AUTOSAR XML (schema 00047)
package /ApplicationSwComponentTypesAR
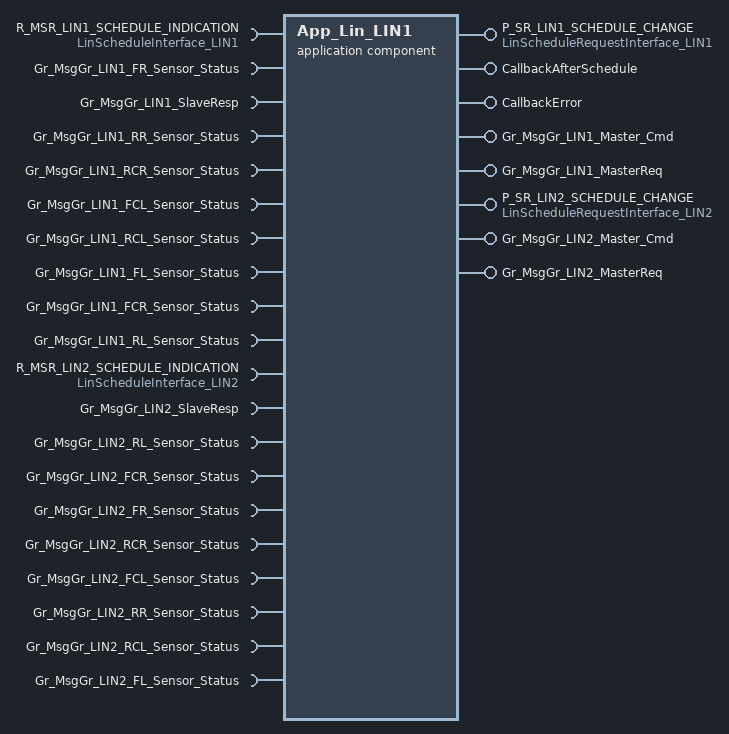
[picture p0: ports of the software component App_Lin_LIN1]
  application sw component type App_Lin_LIN1
    require port R_MSR_LIN1_SCHEDULE_INDICATION: mode-switch-receiver-com-spec{enhanced-mode-api=true, mode-group=LinSchedule_LIN1, supports-asynchronous-mode-switch=true}, required-interface=LinScheduleInterface_LIN1
    5 x provide port:
      P_SR_LIN1_SCHEDULE_CHANGE: nonqueued-sender-com-spec=data-element=LinSchedule_LIN1, provided-interface=LinScheduleRequestInterface_LIN1
      CallbackAfterSchedule: server-com-spec{operation=lin_after_schedule, queue-length=1}, provided-interface=CallbackAfterSchedule
      CallbackError: server-com-spec{operation=lin_cbk_err, queue-length=1}, provided-interface=CallbackError
      Gr_MsgGr_LIN1_Master_Cmd: nonqueued-sender-com-spec=data-element=MsgGr_LIN1_Master_Cmd, provided-interface=Gr_MsgGr_LIN1_Master_Cmd
      Gr_MsgGr_LIN1_MasterReq: nonqueued-sender-com-spec=data-element=MsgGr_LIN1_MasterReq, provided-interface=Gr_MsgGr_LIN1_MasterReq
    10 x require port:
      Gr_MsgGr_LIN1_FR_Sensor_Status: nonqueued-receiver-com-spec=data-element=MsgGr_LIN1_FR_Sensor_Status, required-interface=Gr_MsgGr_LIN1_FR_Sensor_Status
      Gr_MsgGr_LIN1_SlaveResp: nonqueued-receiver-com-spec=data-element=MsgGr_LIN1_SlaveResp, required-interface=Gr_MsgGr_LIN1_SlaveResp
      Gr_MsgGr_LIN1_RR_Sensor_Status: nonqueued-receiver-com-spec=data-element=MsgGr_LIN1_RR_Sensor_Status, required-interface=Gr_MsgGr_LIN1_RR_Sensor_Status
      Gr_MsgGr_LIN1_RCR_Sensor_Status: nonqueued-receiver-com-spec=data-element=MsgGr_LIN1_RCR_Sensor_Status, required-interface=Gr_MsgGr_LIN1_RCR_Sensor_Status
      Gr_MsgGr_LIN1_FCL_Sensor_Status: nonqueued-receiver-com-spec=data-element=MsgGr_LIN1_FCL_Sensor_Status, required-interface=Gr_MsgGr_LIN1_FCL_Sensor_Status
      Gr_MsgGr_LIN1_RCL_Sensor_Status: nonqueued-receiver-com-spec=data-element=MsgGr_LIN1_RCL_Sensor_Status, required-interface=Gr_MsgGr_LIN1_RCL_Sensor_Status
      Gr_MsgGr_LIN1_FL_Sensor_Status: nonqueued-receiver-com-spec=data-element=MsgGr_LIN1_FL_Sensor_Status, required-interface=Gr_MsgGr_LIN1_FL_Sensor_Status
      Gr_MsgGr_LIN1_FCR_Sensor_Status: nonqueued-receiver-com-spec=data-element=MsgGr_LIN1_FCR_Sensor_Status, required-interface=Gr_MsgGr_LIN1_FCR_Sensor_Status
      Gr_MsgGr_LIN1_RL_Sensor_Status: nonqueued-receiver-com-spec=data-element=MsgGr_LIN1_RL_Sensor_Status, required-interface=Gr_MsgGr_LIN1_RL_Sensor_Status
      R_MSR_LIN2_SCHEDULE_INDICATION: mode-switch-receiver-com-spec{enhanced-mode-api=true, mode-group=LinSchedule_LIN2, supports-asynchronous-mode-switch=true}, required-interface=LinScheduleInterface_LIN2
    provide port P_SR_LIN2_SCHEDULE_CHANGE: nonqueued-sender-com-spec=LinSchedule_LIN2, provided-interface=LinScheduleRequestInterface_LIN2
    provide port Gr_MsgGr_LIN2_Master_Cmd: nonqueued-sender-com-spec=MsgGr_LIN2_Master_Cmd, provided-interface=Gr_MsgGr_LIN2_Master_Cmd
    provide port Gr_MsgGr_LIN2_MasterReq: nonqueued-sender-com-spec=MsgGr_LIN2_MasterReq, provided-interface=Gr_MsgGr_LIN2_MasterReq
    9 x require port:
      Gr_MsgGr_LIN2_SlaveResp: nonqueued-receiver-com-spec=data-element=MsgGr_LIN2_SlaveResp, required-interface=Gr_MsgGr_LIN2_SlaveResp
      Gr_MsgGr_LIN2_RL_Sensor_Status: nonqueued-receiver-com-spec=data-element=MsgGr_LIN2_RL_Sensor_Status, required-interface=Gr_MsgGr_LIN2_RL_Sensor_Status
      Gr_MsgGr_LIN2_FCR_Sensor_Status: nonqueued-receiver-com-spec=data-element=MsgGr_LIN2_FCR_Sensor_Status, required-interface=Gr_MsgGr_LIN2_FCR_Sensor_Status
      Gr_MsgGr_LIN2_FR_Sensor_Status: nonqueued-receiver-com-spec=data-element=MsgGr_LIN2_FR_Sensor_Status, required-interface=Gr_MsgGr_LIN2_FR_Sensor_Status
      Gr_MsgGr_LIN2_RCR_Sensor_Status: nonqueued-receiver-com-spec=data-element=MsgGr_LIN2_RCR_Sensor_Status, required-interface=Gr_MsgGr_LIN2_RCR_Sensor_Status
      Gr_MsgGr_LIN2_FCL_Sensor_Status: nonqueued-receiver-com-spec=data-element=MsgGr_LIN2_FCL_Sensor_Status, required-interface=Gr_MsgGr_LIN2_FCL_Sensor_Status
      Gr_MsgGr_LIN2_RR_Sensor_Status: nonqueued-receiver-com-spec=data-element=MsgGr_LIN2_RR_Sensor_Status, required-interface=Gr_MsgGr_LIN2_RR_Sensor_Status
      Gr_MsgGr_LIN2_RCL_Sensor_Status: nonqueued-receiver-com-spec=data-element=MsgGr_LIN2_RCL_Sensor_Status, required-interface=Gr_MsgGr_LIN2_RCL_Sensor_Status
      Gr_MsgGr_LIN2_FL_Sensor_Status: nonqueued-receiver-com-spec=data-element=MsgGr_LIN2_FL_Sensor_Status, required-interface=Gr_MsgGr_LIN2_FL_Sensor_Status
    behavior SwcIB_App_LIN1: data-type-mapping=[MAP_LinSMState, MAP_LinSchedule_LIN1, MAP_LinSchedule_LIN2], handle-termination-and-restart=NO-SUPPORT
      operation invoked event OIE_RE_after_schedule_CBAfterSchedule_lin_after_schedule: start-on-event=RE_after_schedule, operation=CallbackAfterSchedule.lin_after_schedule
      operation invoked event OIE_RE_cbk_err_CBCbkErr_lin_cbk_err: start-on-event=RE_cbk_err, operation=CallbackError.lin_cbk_err
      46 x swc mode switch event, all with activation=ON-ENTRY:
        SMSE_Entry_Lin_LIN1_ScheduleSwitch_R_MSR_LIN_SCHEDULE_INDICATION_LinSchedule_LIN1_NULL: start-on-event=Lin_LIN1_ScheduleSwitch, mode=R_MSR_LIN1_SCHEDULE_INDICATION.LinSchedule_LIN1.NULL
        SMSE_Entry_Lin_LIN1_ScheduleSwitch_R_MSR_LIN_SCHEDULE_INDICATION_LinSchedule_LIN1_SCHEDULER_FPAS_TUNNING_WRITE: start-on-event=Lin_LIN1_ScheduleSwitch, mode=R_MSR_LIN1_SCHEDULE_INDICATION.LinSchedule_LIN1.SCHEDULER_FPAS_TUNNING_WRITE
        SMSE_Entry_Lin_LIN1_ScheduleSwitch_R_MSR_LIN_SCHEDULE_INDICATION_LinSchedule_LIN1_SCHEDULER_FPAS_VER_CHECK: start-on-event=Lin_LIN1_ScheduleSwitch, mode=R_MSR_LIN1_SCHEDULE_INDICATION.LinSchedule_LIN1.SCHEDULER_FPAS_VER_CHECK
        SMSE_Entry_Lin_LIN1_ScheduleSwitch_R_MSR_LIN_SCHEDULE_INDICATION_LinSchedule_LIN1_SCHEDULER_FRONT_PAS_NORMAL: start-on-event=Lin_LIN1_ScheduleSwitch, mode=R_MSR_LIN1_SCHEDULE_INDICATION.LinSchedule_LIN1.SCHEDULER_FRONT_PAS_NORMAL
        SMSE_Entry_Lin_LIN1_ScheduleSwitch_R_MSR_LIN_SCHEDULE_INDICATION_LinSchedule_LIN1_SCHEDULER_PAS_CRC_COMPARE: start-on-event=Lin_LIN1_ScheduleSwitch, mode=R_MSR_LIN1_SCHEDULE_INDICATION.LinSchedule_LIN1.SCHEDULER_PAS_CRC_COMPARE
        SMSE_Entry_Lin_LIN1_ScheduleSwitch_R_MSR_LIN_SCHEDULE_INDICATION_LinSchedule_LIN1_SCHEDULER_PAS_DIAG: start-on-event=Lin_LIN1_ScheduleSwitch, mode=R_MSR_LIN1_SCHEDULE_INDICATION.LinSchedule_LIN1.SCHEDULER_PAS_DIAG
        SMSE_Entry_Lin_LIN1_ScheduleSwitch_R_MSR_LIN_SCHEDULE_INDICATION_LinSchedule_LIN1_SCHEDULER_PAS_DIAG_FCL: start-on-event=Lin_LIN1_ScheduleSwitch, mode=R_MSR_LIN1_SCHEDULE_INDICATION.LinSchedule_LIN1.SCHEDULER_PAS_DIAG_FCL
        SMSE_Entry_Lin_LIN1_ScheduleSwitch_R_MSR_LIN_SCHEDULE_INDICATION_LinSchedule_LIN1_SCHEDULER_PAS_DIAG_FCR: start-on-event=Lin_LIN1_ScheduleSwitch, mode=R_MSR_LIN1_SCHEDULE_INDICATION.LinSchedule_LIN1.SCHEDULER_PAS_DIAG_FCR
        SMSE_Entry_Lin_LIN1_ScheduleSwitch_R_MSR_LIN_SCHEDULE_INDICATION_LinSchedule_LIN1_SCHEDULER_PAS_DIAG_FL: start-on-event=Lin_LIN1_ScheduleSwitch, mode=R_MSR_LIN1_SCHEDULE_INDICATION.LinSchedule_LIN1.SCHEDULER_PAS_DIAG_FL
        SMSE_Entry_Lin_LIN1_ScheduleSwitch_R_MSR_LIN_SCHEDULE_INDICATION_LinSchedule_LIN1_SCHEDULER_PAS_DIAG_FR: start-on-event=Lin_LIN1_ScheduleSwitch, mode=R_MSR_LIN1_SCHEDULE_INDICATION.LinSchedule_LIN1.SCHEDULER_PAS_DIAG_FR
        SMSE_Entry_Lin_LIN1_ScheduleSwitch_R_MSR_LIN_SCHEDULE_INDICATION_LinSchedule_LIN1_SCHEDULER_PAS_DIAG_IBU: start-on-event=Lin_LIN1_ScheduleSwitch, mode=R_MSR_LIN1_SCHEDULE_INDICATION.LinSchedule_LIN1.SCHEDULER_PAS_DIAG_IBU
        SMSE_Entry_Lin_LIN1_ScheduleSwitch_R_MSR_LIN_SCHEDULE_INDICATION_LinSchedule_LIN1_SCHEDULER_PAS_DIAG_RCL: start-on-event=Lin_LIN1_ScheduleSwitch, mode=R_MSR_LIN1_SCHEDULE_INDICATION.LinSchedule_LIN1.SCHEDULER_PAS_DIAG_RCL
        SMSE_Entry_Lin_LIN1_ScheduleSwitch_R_MSR_LIN_SCHEDULE_INDICATION_LinSchedule_LIN1_SCHEDULER_PAS_DIAG_RCR: start-on-event=Lin_LIN1_ScheduleSwitch, mode=R_MSR_LIN1_SCHEDULE_INDICATION.LinSchedule_LIN1.SCHEDULER_PAS_DIAG_RCR
        SMSE_Entry_Lin_LIN1_ScheduleSwitch_R_MSR_LIN_SCHEDULE_INDICATION_LinSchedule_LIN1_SCHEDULER_PAS_DIAG_RL: start-on-event=Lin_LIN1_ScheduleSwitch, mode=R_MSR_LIN1_SCHEDULE_INDICATION.LinSchedule_LIN1.SCHEDULER_PAS_DIAG_RL
        SMSE_Entry_Lin_LIN1_ScheduleSwitch_R_MSR_LIN_SCHEDULE_INDICATION_LinSchedule_LIN1_SCHEDULER_PAS_DIAG_RR: start-on-event=Lin_LIN1_ScheduleSwitch, mode=R_MSR_LIN1_SCHEDULE_INDICATION.LinSchedule_LIN1.SCHEDULER_PAS_DIAG_RR
        SMSE_Entry_Lin_LIN1_ScheduleSwitch_R_MSR_LIN_SCHEDULE_INDICATION_LinSchedule_LIN1_SCHEDULER_PAS_NORMAL: start-on-event=Lin_LIN1_ScheduleSwitch, mode=R_MSR_LIN1_SCHEDULE_INDICATION.LinSchedule_LIN1.SCHEDULER_PAS_NORMAL
        SMSE_Entry_Lin_LIN1_ScheduleSwitch_R_MSR_LIN_SCHEDULE_INDICATION_LinSchedule_LIN1_SCHEDULER_PAS_SENSOR_REQUEST: start-on-event=Lin_LIN1_ScheduleSwitch, mode=R_MSR_LIN1_SCHEDULE_INDICATION.LinSchedule_LIN1.SCHEDULER_PAS_SENSOR_REQUEST
        SMSE_Entry_Lin_LIN1_ScheduleSwitch_R_MSR_LIN_SCHEDULE_INDICATION_LinSchedule_LIN1_SCHEDULER_PAS_TEMP_COMP: start-on-event=Lin_LIN1_ScheduleSwitch, mode=R_MSR_LIN1_SCHEDULE_INDICATION.LinSchedule_LIN1.SCHEDULER_PAS_TEMP_COMP
        SMSE_Entry_Lin_LIN1_ScheduleSwitch_R_MSR_LIN_SCHEDULE_INDICATION_LinSchedule_LIN1_SCHEDULER_RPAS_CRC_COMPARE: start-on-event=Lin_LIN1_ScheduleSwitch, mode=R_MSR_LIN1_SCHEDULE_INDICATION.LinSchedule_LIN1.SCHEDULER_RPAS_CRC_COMPARE
        SMSE_Entry_Lin_LIN1_ScheduleSwitch_R_MSR_LIN_SCHEDULE_INDICATION_LinSchedule_LIN1_SCHEDULER_RPAS_NORMAL: start-on-event=Lin_LIN1_ScheduleSwitch, mode=R_MSR_LIN1_SCHEDULE_INDICATION.LinSchedule_LIN1.SCHEDULER_RPAS_NORMAL
        SMSE_Entry_Lin_LIN1_ScheduleSwitch_R_MSR_LIN_SCHEDULE_INDICATION_LinSchedule_LIN1_SCHEDULER_RPAS_TEMP_COMP: start-on-event=Lin_LIN1_ScheduleSwitch, mode=R_MSR_LIN1_SCHEDULE_INDICATION.LinSchedule_LIN1.SCHEDULER_RPAS_TEMP_COMP
        SMSE_Entry_Lin_LIN1_ScheduleSwitch_R_MSR_LIN_SCHEDULE_INDICATION_LinSchedule_LIN1_SCHEDULER_RPAS_TUNNING_WRITE: start-on-event=Lin_LIN1_ScheduleSwitch, mode=R_MSR_LIN1_SCHEDULE_INDICATION.LinSchedule_LIN1.SCHEDULER_RPAS_TUNNING_WRITE
        SMSE_Entry_Lin_LIN1_ScheduleSwitch_R_MSR_LIN_SCHEDULE_INDICATION_LinSchedule_LIN1_SCHEDULER_RPAS_VER_CHECK: start-on-event=Lin_LIN1_ScheduleSwitch, mode=R_MSR_LIN1_SCHEDULE_INDICATION.LinSchedule_LIN1.SCHEDULER_RPAS_VER_CHECK
        SMSE_Entry_Lin_LIN2_ScheduleSwitch_R_MSR_LIN2_SCHEDULE_INDICATION_LinSchedule_LIN2_NULL: start-on-event=Lin_LIN2_ScheduleSwitch, mode=R_MSR_LIN2_SCHEDULE_INDICATION.LinSchedule_LIN2.NULL
        SMSE_Entry_Lin_LIN2_ScheduleSwitch_R_MSR_LIN2_SCHEDULE_INDICATION_LinSchedule_LIN2_SCHEDULER_FPAS_TUNNING_WRITE: start-on-event=Lin_LIN2_ScheduleSwitch, mode=R_MSR_LIN2_SCHEDULE_INDICATION.LinSchedule_LIN2.SCHEDULER_FPAS_TUNNING_WRITE
        SMSE_Entry_Lin_LIN2_ScheduleSwitch_R_MSR_LIN2_SCHEDULE_INDICATION_LinSchedule_LIN2_SCHEDULER_FPAS_VER_CHECK: start-on-event=Lin_LIN2_ScheduleSwitch, mode=R_MSR_LIN2_SCHEDULE_INDICATION.LinSchedule_LIN2.SCHEDULER_FPAS_VER_CHECK
        SMSE_Entry_Lin_LIN2_ScheduleSwitch_R_MSR_LIN2_SCHEDULE_INDICATION_LinSchedule_LIN2_SCHEDULER_FRONT_PAS_NORMAL: start-on-event=Lin_LIN2_ScheduleSwitch, mode=R_MSR_LIN2_SCHEDULE_INDICATION.LinSchedule_LIN2.SCHEDULER_FRONT_PAS_NORMAL
        SMSE_Entry_Lin_LIN2_ScheduleSwitch_R_MSR_LIN2_SCHEDULE_INDICATION_LinSchedule_LIN2_SCHEDULER_PAS_CRC_COMPARE: start-on-event=Lin_LIN2_ScheduleSwitch, mode=R_MSR_LIN2_SCHEDULE_INDICATION.LinSchedule_LIN2.SCHEDULER_PAS_CRC_COMPARE
        SMSE_Entry_Lin_LIN2_ScheduleSwitch_R_MSR_LIN2_SCHEDULE_INDICATION_LinSchedule_LIN2_SCHEDULER_PAS_DIAG: start-on-event=Lin_LIN2_ScheduleSwitch, mode=R_MSR_LIN2_SCHEDULE_INDICATION.LinSchedule_LIN2.SCHEDULER_PAS_DIAG
        SMSE_Entry_Lin_LIN2_ScheduleSwitch_R_MSR_LIN2_SCHEDULE_INDICATION_LinSchedule_LIN2_SCHEDULER_PAS_DIAG_FCL: start-on-event=Lin_LIN2_ScheduleSwitch, mode=R_MSR_LIN2_SCHEDULE_INDICATION.LinSchedule_LIN2.SCHEDULER_PAS_DIAG_FCL
        SMSE_Entry_Lin_LIN2_ScheduleSwitch_R_MSR_LIN2_SCHEDULE_INDICATION_LinSchedule_LIN2_SCHEDULER_PAS_DIAG_FCR: start-on-event=Lin_LIN2_ScheduleSwitch, mode=R_MSR_LIN2_SCHEDULE_INDICATION.LinSchedule_LIN2.SCHEDULER_PAS_DIAG_FCR
        SMSE_Entry_Lin_LIN2_ScheduleSwitch_R_MSR_LIN2_SCHEDULE_INDICATION_LinSchedule_LIN2_SCHEDULER_PAS_DIAG_FL: start-on-event=Lin_LIN2_ScheduleSwitch, mode=R_MSR_LIN2_SCHEDULE_INDICATION.LinSchedule_LIN2.SCHEDULER_PAS_DIAG_FL
        SMSE_Entry_Lin_LIN2_ScheduleSwitch_R_MSR_LIN2_SCHEDULE_INDICATION_LinSchedule_LIN2_SCHEDULER_PAS_DIAG_FR: start-on-event=Lin_LIN2_ScheduleSwitch, mode=R_MSR_LIN2_SCHEDULE_INDICATION.LinSchedule_LIN2.SCHEDULER_PAS_DIAG_FR
        SMSE_Entry_Lin_LIN2_ScheduleSwitch_R_MSR_LIN2_SCHEDULE_INDICATION_LinSchedule_LIN2_SCHEDULER_PAS_DIAG_IBU: start-on-event=Lin_LIN2_ScheduleSwitch, mode=R_MSR_LIN2_SCHEDULE_INDICATION.LinSchedule_LIN2.SCHEDULER_PAS_DIAG_IBU
        SMSE_Entry_Lin_LIN2_ScheduleSwitch_R_MSR_LIN2_SCHEDULE_INDICATION_LinSchedule_LIN2_SCHEDULER_PAS_DIAG_RCL: start-on-event=Lin_LIN2_ScheduleSwitch, mode=R_MSR_LIN2_SCHEDULE_INDICATION.LinSchedule_LIN2.SCHEDULER_PAS_DIAG_RCL
        SMSE_Entry_Lin_LIN2_ScheduleSwitch_R_MSR_LIN2_SCHEDULE_INDICATION_LinSchedule_LIN2_SCHEDULER_PAS_DIAG_RCR: start-on-event=Lin_LIN2_ScheduleSwitch, mode=R_MSR_LIN2_SCHEDULE_INDICATION.LinSchedule_LIN2.SCHEDULER_PAS_DIAG_RCR
        SMSE_Entry_Lin_LIN2_ScheduleSwitch_R_MSR_LIN2_SCHEDULE_INDICATION_LinSchedule_LIN2_SCHEDULER_PAS_DIAG_RL: start-on-event=Lin_LIN2_ScheduleSwitch, mode=R_MSR_LIN2_SCHEDULE_INDICATION.LinSchedule_LIN2.SCHEDULER_PAS_DIAG_RL
        SMSE_Entry_Lin_LIN2_ScheduleSwitch_R_MSR_LIN2_SCHEDULE_INDICATION_LinSchedule_LIN2_SCHEDULER_PAS_DIAG_RR: start-on-event=Lin_LIN2_ScheduleSwitch, mode=R_MSR_LIN2_SCHEDULE_INDICATION.LinSchedule_LIN2.SCHEDULER_PAS_DIAG_RR
        SMSE_Entry_Lin_LIN2_ScheduleSwitch_R_MSR_LIN2_SCHEDULE_INDICATION_LinSchedule_LIN2_SCHEDULER_PAS_NORMAL: start-on-event=Lin_LIN2_ScheduleSwitch, mode=R_MSR_LIN2_SCHEDULE_INDICATION.LinSchedule_LIN2.SCHEDULER_PAS_NORMAL
        SMSE_Entry_Lin_LIN2_ScheduleSwitch_R_MSR_LIN2_SCHEDULE_INDICATION_LinSchedule_LIN2_SCHEDULER_PAS_SENSOR_REQUEST: start-on-event=Lin_LIN2_ScheduleSwitch, mode=R_MSR_LIN2_SCHEDULE_INDICATION.LinSchedule_LIN2.SCHEDULER_PAS_SENSOR_REQUEST
        SMSE_Entry_Lin_LIN2_ScheduleSwitch_R_MSR_LIN2_SCHEDULE_INDICATION_LinSchedule_LIN2_SCHEDULER_PAS_TEMP_COMP: start-on-event=Lin_LIN2_ScheduleSwitch, mode=R_MSR_LIN2_SCHEDULE_INDICATION.LinSchedule_LIN2.SCHEDULER_PAS_TEMP_COMP
        SMSE_Entry_Lin_LIN2_ScheduleSwitch_R_MSR_LIN2_SCHEDULE_INDICATION_LinSchedule_LIN2_SCHEDULER_RPAS_CRC_COMPARE: start-on-event=Lin_LIN2_ScheduleSwitch, mode=R_MSR_LIN2_SCHEDULE_INDICATION.LinSchedule_LIN2.SCHEDULER_RPAS_CRC_COMPARE
        SMSE_Entry_Lin_LIN2_ScheduleSwitch_R_MSR_LIN2_SCHEDULE_INDICATION_LinSchedule_LIN2_SCHEDULER_RPAS_NORMAL: start-on-event=Lin_LIN2_ScheduleSwitch, mode=R_MSR_LIN2_SCHEDULE_INDICATION.LinSchedule_LIN2.SCHEDULER_RPAS_NORMAL
        SMSE_Entry_Lin_LIN2_ScheduleSwitch_R_MSR_LIN2_SCHEDULE_INDICATION_LinSchedule_LIN2_SCHEDULER_RPAS_TEMP_COMP: start-on-event=Lin_LIN2_ScheduleSwitch, mode=R_MSR_LIN2_SCHEDULE_INDICATION.LinSchedule_LIN2.SCHEDULER_RPAS_TEMP_COMP
        SMSE_Entry_Lin_LIN2_ScheduleSwitch_R_MSR_LIN2_SCHEDULE_INDICATION_LinSchedule_LIN2_SCHEDULER_RPAS_TUNNING_WRITE: start-on-event=Lin_LIN2_ScheduleSwitch, mode=R_MSR_LIN2_SCHEDULE_INDICATION.LinSchedule_LIN2.SCHEDULER_RPAS_TUNNING_WRITE
        SMSE_Entry_Lin_LIN2_ScheduleSwitch_R_MSR_LIN2_SCHEDULE_INDICATION_LinSchedule_LIN2_SCHEDULER_RPAS_VER_CHECK: start-on-event=Lin_LIN2_ScheduleSwitch, mode=R_MSR_LIN2_SCHEDULE_INDICATION.LinSchedule_LIN2.SCHEDULER_RPAS_VER_CHECK
      6 x runnable:
        Lin_LIN1_ScheduleRequest: symbol=Sym_LinScheduleRequest_LIN1
          data-send-points:
            access VariableAccess0: accessed-variable=P_SR_LIN1_SCHEDULE_CHANGE.LinSchedule_LIN1
        RE_after_schedule: can-be-invoked-concurrently=true, symbol=lin_after_schedule
        RE_cbk_err: can-be-invoked-concurrently=true, symbol=lin_cbk_err
        Lin_LIN1_ScheduleSwitch: can-be-invoked-concurrently=true, symbol=Sym_LinScheduleSwitch_LIN1
          mode-access-point mode-group=R_MSR_LIN1_SCHEDULE_INDICATION.LinSchedule_LIN1:
            ident MRAP_Lin_LIN1_ScheduleSwitch_R_MSR_LIN_SCHEDULE_INDICATION_LinSchedule_LIN1
        Lin_LIN2_ScheduleRequest: symbol=Sym_LinScheduleRequest_LIN2
          data-send-points:
            access DSP_Lin_LIN2_ScheduleRequest_P_SR_LIN2_SCHEDULE_CHANGE_LinSchedule_LIN2: accessed-variable=P_SR_LIN2_SCHEDULE_CHANGE.LinSchedule_LIN2, scope=COMMUNICATION-INTER-ECU
        Lin_LIN2_ScheduleSwitch: can-be-invoked-concurrently=true, symbol=Sym_LinScheduleSwitch_LIN2
          mode-access-point mode-group=R_MSR_LIN2_SCHEDULE_INDICATION.LinSchedule_LIN2:
            ident MRAP_Lin_LIN2_ScheduleSwitch_R_MSR_LIN2_SCHEDULE_INDICATION_LinSchedule_LIN2
      swc service dependency SwcServiceDependency0
        assigned-ports:
          port-prototype=P_SR_LIN1_SCHEDULE_CHANGE, role=Custom
          port-prototype=R_MSR_LIN1_SCHEDULE_INDICATION, role=Custom
          port-prototype=P_SR_LIN2_SCHEDULE_CHANGE, role=Custom
          port-prototype=R_MSR_LIN2_SCHEDULE_INDICATION, role=Custom
        service-needs:
          bsw mgr needs BswMgrNeeds
